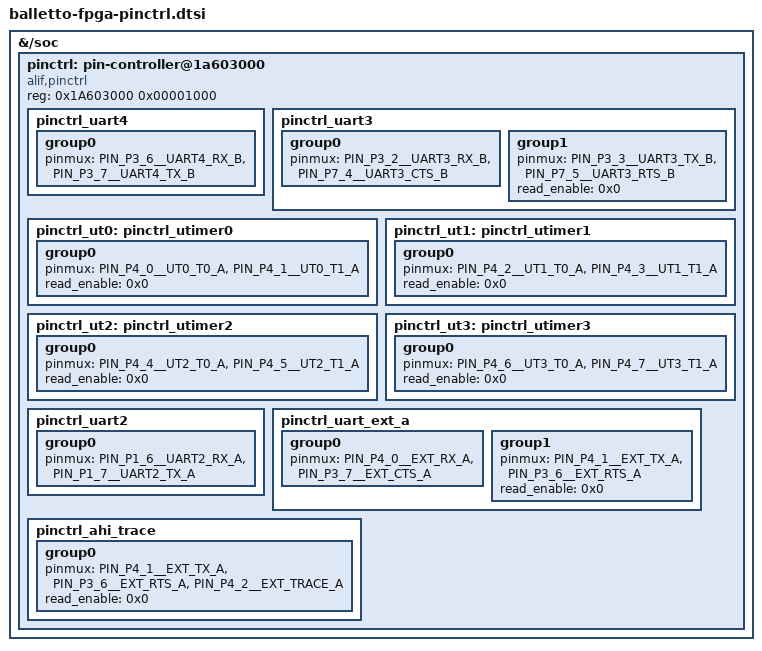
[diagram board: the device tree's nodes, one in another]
/* Copyright (c) 2024 Alif Semiconductor
 *
 * SPDX-License-Identifier: Apache-2.0
 */
#include <dt-bindings/pinctrl/balletto-fpga-pinctrl.h>
&{/soc} {
	pinctrl: pin-controller@1a603000 {
		compatible = "alif,pinctrl";
		reg =   <0x1A603000 0x00001000>;
	};
};

&pinctrl {
	pinctrl_uart4: pinctrl_uart4 {
		group0 {
			pinmux = < PIN_P3_6__UART4_RX_B >,
				 < PIN_P3_7__UART4_TX_B >;
			/* pad config default values
			 * read_enable = < 0x1 >; 0 for disable, 1 for enable
			 * schmitt_enable = < 0x1 >; 0x0 for disable
			 *			  0x1 for enable
			 * slew_rate = < 0x0 > ; 0 for slow, 1 for fast
			 * driver_state_control = <0>;
			 *			0 for high z
			 *			1 for pull up
			 *			2 for pull down
			 *			3 for bus repeater
			 * drive_strength = <4>;
			 *			2 for 2mA
			 *			4 for 4mA
			 *			8 for 8mA
			 *			12 for 12mA
			 * driver = < 0x0 >; 0 for push pull, 1 for open drain
			 */
		};
	};
	pinctrl_uart3: pinctrl_uart3 {
		group0 {
			pinmux = < PIN_P3_2__UART3_RX_B >,
				 < PIN_P7_4__UART3_CTS_B >;
		};
		group1 {
			pinmux = < PIN_P3_3__UART3_TX_B >,
				 < PIN_P7_5__UART3_RTS_B >;
			read_enable = < 0x0 >;
		};
	};

	pinctrl_ut0: pinctrl_utimer0 {
		group0 {
			pinmux = < PIN_P4_0__UT0_T0_A >,
				 < PIN_P4_1__UT0_T1_A >;
			read_enable = < 0x0 >;
		};
	};

	pinctrl_ut1: pinctrl_utimer1 {
		group0 {
			pinmux = < PIN_P4_2__UT1_T0_A >,
				 < PIN_P4_3__UT1_T1_A >;
			read_enable = < 0x0 >;
		};
	};

	pinctrl_ut2: pinctrl_utimer2 {
		group0 {
			pinmux = < PIN_P4_4__UT2_T0_A >,
				 < PIN_P4_5__UT2_T1_A >;
			read_enable = < 0x0 >;
		};
	};

	pinctrl_ut3: pinctrl_utimer3 {
		group0 {
			pinmux = < PIN_P4_6__UT3_T0_A >,
				 < PIN_P4_7__UT3_T1_A >;
			read_enable = < 0x0 >;
		};
	};

	pinctrl_uart2: pinctrl_uart2 {
		group0 {
			pinmux = < PIN_P1_6__UART2_RX_A >,
				 < PIN_P1_7__UART2_TX_A >;
		};
	};

	pinctrl_uart_ext_a: pinctrl_uart_ext_a {
		group0 {
			pinmux = < PIN_P4_0__EXT_RX_A >,
				 < PIN_P3_7__EXT_CTS_A >;
		};
		group1 {
			pinmux = < PIN_P4_1__EXT_TX_A >,
				 < PIN_P3_6__EXT_RTS_A >;
			read_enable = < 0x0 >;
		};
	};
	pinctrl_ahi_trace: pinctrl_ahi_trace {
		group0 {
			pinmux = < PIN_P4_1__EXT_TX_A >,
				 < PIN_P3_6__EXT_RTS_A >,
				 < PIN_P4_2__EXT_TRACE_A >;
			read_enable = < 0x0 >;
		};
	};
};
